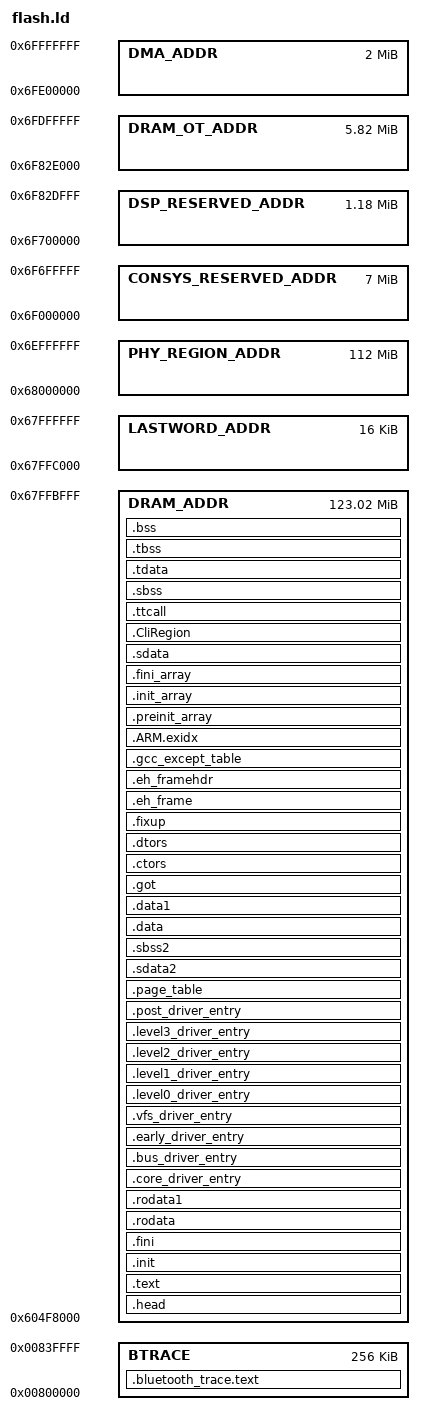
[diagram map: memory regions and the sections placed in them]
/*******************************************************************/
/*                                                                 */
/* This file is automatically generated by linker script generator.*/
/*                                                                 */
/* Version:                                 */
/*                                                                 */
/* Copyright (c) 2010 Xilinx, Inc.  All rights reserved.           */
/*                                                                 */
/* Description : Cortex-A9 Linker Script                          */
/*                                                                 */
/*******************************************************************/

/* Specify the default entry point to the program */
ENTRY(_vector_table)

/* Define Memories in the system */
MEMORY
{
   DRAM_ADDR : ORIGIN = 0x604f8000, LENGTH = 0x7b04000   /*  ~ 123M */
   LASTWORD_ADDR : ORIGIN = 0x67ffc000, LENGTH = 0x4000  /* 16K, reserve for last word */
   PHY_REGION_ADDR : ORIGIN = 0x68000000, LENGTH = 0x7000000 /* 112M for phy region */
   CONSYS_RESERVED_ADDR : ORIGIN = 0x6f000000  LENGTH = 0x700000 /*align 16M for consys memory reserved*/
   DSP_RESERVED_ADDR : ORIGIN = 0x6f700000  LENGTH = 0x12e000 /*for dsp memory reserved*/
   DRAM_OT_ADDR : ORIGIN = 0x6f82e000, LENGTH = 0x5d2000 /*for other dram space can be used*/
   DMA_ADDR :  ORIGIN = 0x6fe00000, LENGTH = 0x200000 /*for DMA dram space can be used*/
   BTRACE : ORIGIN = 0x00800000, LENGTH = 0x40000
}

/* Define the sections, and where they are mapped in memory */
SECTIONS
{
.head : {
   __head_start = .;
   KEEP(*(.head))
   . = ALIGN(32);
   __head_end = .;
} > DRAM_ADDR

.text : {
   __text_start = .;
   KEEP(*(.vectors))
   *(.boot)
   *(.text)
   *(.text.*)
   *(.gnu.linkonce.t.*)
   *(.plt)
   *(.gnu_warning)
   *(.gcc_execpt_table)
   *(.glue_7)
   *(.glue_7t)
   *(.vfp11_veneer)
   *(.ARM.extab)
   *(.gnu.linkonce.armextab.*)
   __text_end = .;
} > DRAM_ADDR

.init : {
   __init_start = .;
   KEEP (*(.init))
   __init_end = .;
} > DRAM_ADDR

.fini : {
   __fini_start = .;
   KEEP (*(.fini))
   __fini_end = .;
} > DRAM_ADDR

.rodata : {
   __rodata_start = .;
   *(.rodata)
   *(.rodata.*)
   *(.gnu.linkonce.r.*)
   __rodata_end = .;
} > DRAM_ADDR

.rodata1 : {
   __rodata1_start = .;
   *(.rodata1)
   *(.rodata1.*)
   . = ALIGN(0x1000);
   __rodata1_end = .;
} > DRAM_ADDR

 .core_driver_entry (.):
 {
  __core_driver_start__ = .;
  KEEP(*(.core_driver_entry))
  . = ALIGN(4);
  __core_driver_end__ = .;
 } > DRAM_ADDR

 .bus_driver_entry (.):
 {
  __bus_driver_start__ = .;
  KEEP(*(*.bus_driver_entry))
  __bus_driver_end__ = .;
 } >DRAM_ADDR

 .early_driver_entry (.):
  {
   __early_driver_start__ = .;
   KEEP(*(*.early_driver_entry))
   __early_driver_end__ = .;
  } >DRAM_ADDR

 .vfs_driver_entry (.):
  {
   __vfs_driver_start__ = .;
   KEEP(*(*.vfs_driver_entry))
   __vfs_driver_end__ = .;
  } >DRAM_ADDR

 .level0_driver_entry (.):
  {
   __level0_driver_start__ = .;
   KEEP(*(*.level0_driver_entry))
   __level0_driver_end__ = .;
  } >DRAM_ADDR

 .level1_driver_entry (.):
  {
   __level1_driver_start__ = .;
   KEEP(*(*.level1_driver_entry))
   __level1_driver_end__ = .;
  } >DRAM_ADDR

 .level2_driver_entry (.):
  {
   __level2_driver_start__ = .;
   KEEP(*(*.level2_driver_entry))
   __level2_driver_end__ = .;
  } >DRAM_ADDR

 .level3_driver_entry (.):
  {
   __level3_driver_start__ = .;
   KEEP(*(*.level3_driver_entry))
   __level3_driver_end__ = .;
  } >DRAM_ADDR

 .post_driver_entry (.):
  {
   __post_driver_start__ = .;
   KEEP(*(*.post_driver_entry))
   __post_driver_end__ = .;
  } >DRAM_ADDR

  __kernel_driver_mode__ = 1;
/* MMU L1 page table */
.page_table (NOLOAD) :
{
    *(.mmu_tbl)
} > DRAM_ADDR

.sdata2 : {
   __sdata2_start = .;
   *(.sdata2)
   *(.sdata2.*)
   *(.gnu.linkonce.s2.*)
   __sdata2_end = .;
} > DRAM_ADDR

.sbss2 : {
   __sbss2_start = .;
   *(.sbss2)
   *(.sbss2.*)
   *(.gnu.linkonce.sb2.*)
   __sbss2_end = .;
} > DRAM_ADDR

.data : {
   __data_start = .;
   *(.data)
   *(.data.*)
   *(.gnu.linkonce.d.*)
   *(.jcr)
   *(.got)
   *(.got.plt)
   __data_end = .;
} > DRAM_ADDR

.data1 : {
   __data1_start = .;
   *(.data1)
   *(.data1.*)
   __data1_end = .;
} > DRAM_ADDR

.got : {
   __got_start = .;
   *(.got)
   __got_end = .;
} > DRAM_ADDR

.ctors : {
   __CTOR_LIST__ = .;
   ___CTORS_LIST___ = .;
   KEEP (*crtbegin.o(.ctors))
   KEEP (*(EXCLUDE_FILE(*crtend.o) .ctors))
   KEEP (*(SORT(.ctors.*)))
   KEEP (*(.ctors))
   __CTOR_END__ = .;
   ___CTORS_END___ = .;
} > DRAM_ADDR

.dtors : {
   __DTOR_LIST__ = .;
   ___DTORS_LIST___ = .;
   KEEP (*crtbegin.o(.dtors))
   KEEP (*(EXCLUDE_FILE(*crtend.o) .dtors))
   KEEP (*(SORT(.dtors.*)))
   KEEP (*(.dtors))
   __DTOR_END__ = .;
   ___DTORS_END___ = .;
} > DRAM_ADDR

.fixup : {
   __fixup_start = .;
   *(.fixup)
   __fixup_end = .;
} > DRAM_ADDR

.eh_frame : {
   __en_frame_start = .;
   *(.eh_frame)
   __en_frame_end = .;
} > DRAM_ADDR

.eh_framehdr : {
   __eh_framehdr_start = .;
   *(.eh_framehdr)
   __eh_framehdr_end = .;
} > DRAM_ADDR

.gcc_except_table : {
   __gcc_except_table_start = .;
   *(.gcc_except_table)
   __gcc_except_table_end = .;
} > DRAM_ADDR

.ARM.exidx : {
   __exidx_start = .;
   *(.ARM.exidx*)
   *(.gnu.linkonce.armexidix.*.*)
   __exidx_end = .;
} > DRAM_ADDR

.preinit_array : {
   __preinit_array_start = .;
   KEEP (*(SORT(.preinit_array.*)))
   KEEP (*(.preinit_array))
   __preinit_array_end = .;
} > DRAM_ADDR

.init_array : {
   __init_array_start = .;
   __ctors_start__ = .;
   KEEP (*(SORT(.init_array.*)))
   KEEP (*(.init_array))
   __init_array_end = .;
   __ctors_end__ = .;
} > DRAM_ADDR

.fini_array : {
   __fini_array_start = .;
   __dtors_start__ = .;
   KEEP (*(SORT(.fini_array.*)))
   KEEP (*(.fini_array))
   __fini_array_end = .;
   __dtors_end__ = .;
} > DRAM_ADDR

.sdata : {
   __sdata_start = .;
   *(.sdata)
   *(.sdata.*)
   *(.gnu.linkonce.s.*)
   __sdata_end = .;
} > DRAM_ADDR

.CliRegion : {
    _cli_region_begin = .;
    KEEP(*(CliRegion))
    _cli_region_end = .;
} > DRAM_ADDR

.ttcall : {
   _tt_begin = .;
   KEEP(*(ttcall))
   _tt_end = .;
} > DRAM_ADDR

.sbss (NOLOAD) : {
   __sbss_start = .;
   *(.sbss)
   *(.sbss.*)
   *(.gnu.linkonce.sb.*)
   __sbss_end = .;
} > DRAM_ADDR

.tdata : {
   __tdata_start = .;
   *(.tdata)
   *(.tdata.*)
   *(.gnu.linkonce.td.*)
   __tdata_end = .;
} > DRAM_ADDR

.tbss : {
   __tbss_start = .;
   *(.tbss)
   *(.tbss.*)
   *(.gnu.linkonce.tb.*)
   __tbss_end = .;
} > DRAM_ADDR

.bss (NOLOAD) : {
   __bss_start = .;
   *(.bss)
   *(.bss.*)
   *(.gnu.linkonce.b.*)
   *(COMMON)
   __bss_end = .;
} > DRAM_ADDR


PROVIDE (end = .);

_SDA_BASE_ = __sdata_start + ((__sbss_end - __sdata_start) / 2 );
_SDA2_BASE_ = __sdata2_start + ((__sbss2_end - __sdata2_start) / 2 );

. = ALIGN(16);
_heap_start = .;
_heap_end = ORIGIN(DRAM_ADDR) + LENGTH(DRAM_ADDR);
_heap_len = _heap_end - _heap_start;

_mmu_text_start = ORIGIN(DRAM_ADDR);
_mmu_text_end = __rodata1_end;
_mmu_text_len = _mmu_text_end - _mmu_text_start;

_mmu_data_start = _mmu_text_end;
_mmu_data_end = ORIGIN(DRAM_ADDR) + LENGTH(DRAM_ADDR) + LENGTH(LASTWORD_ADDR);
_mmu_data_len = _mmu_data_end - _mmu_data_start;

_consys_reserved_start = ORIGIN(CONSYS_RESERVED_ADDR);
_consys_reserved_len = LENGTH(CONSYS_RESERVED_ADDR);
_dsp_reserved_start = ORIGIN(DSP_RESERVED_ADDR);
_dsp_reserved_len = LENGTH(DSP_RESERVED_ADDR);
_heap1_start =  ORIGIN(DRAM_OT_ADDR);
_heap1_len = LENGTH(DRAM_OT_ADDR);

_dma_start =  ORIGIN(DMA_ADDR);
_dma_len = LENGTH(DMA_ADDR);

_phy_region_start = ORIGIN(PHY_REGION_ADDR);
_phy_region_len = LENGTH(PHY_REGION_ADDR);

_end = .;

.bluetooth_trace.text : {
    *(.BTTRACE)
} >BTRACE

}
